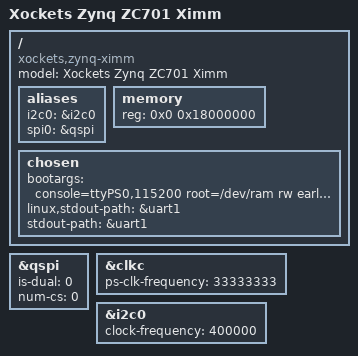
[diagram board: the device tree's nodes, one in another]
/*
 *  Copyright (C) 2011 - 2014 Xilinx
 *  Copyright (C) 2012 National Instruments Corp.
 *
 * This software is licensed under the terms of the GNU General Public
 * License version 2, as published by the Free Software Foundation, and
 * may be copied, distributed, and modified under those terms.
 *
 * This program is distributed in the hope that it will be useful,
 * but WITHOUT ANY WARRANTY; without even the implied warranty of
 * MERCHANTABILITY or FITNESS FOR A PARTICULAR PURPOSE.  See the
 * GNU General Public License for more details.
 */
/dts-v1/;
/include/ "zynq-7000.dtsi"

/ {
	model = "Xockets Zynq ZC701 Ximm";
	compatible = "xockets,zynq-ximm", "xlnx,zynq-7000";

	aliases {
		i2c0 = &i2c0;
		spi0 = &qspi;
	};

	memory {
		device_type = "memory";
		reg = <0x0 0x18000000>;
	};

	chosen {
		bootargs = "console=ttyPS0,115200 root=/dev/ram rw earlyprintk";
		linux,stdout-path = &uart1;
		stdout-path = &uart1;
	};
};

&qspi {
	status = "okay";
	is-dual = <0>;
	num-cs = <0>;
};

&clkc {
	ps-clk-frequency = <33333333>;
};

&i2c0 {
	status = "okay";
	clock-frequency = <400000>;
};
